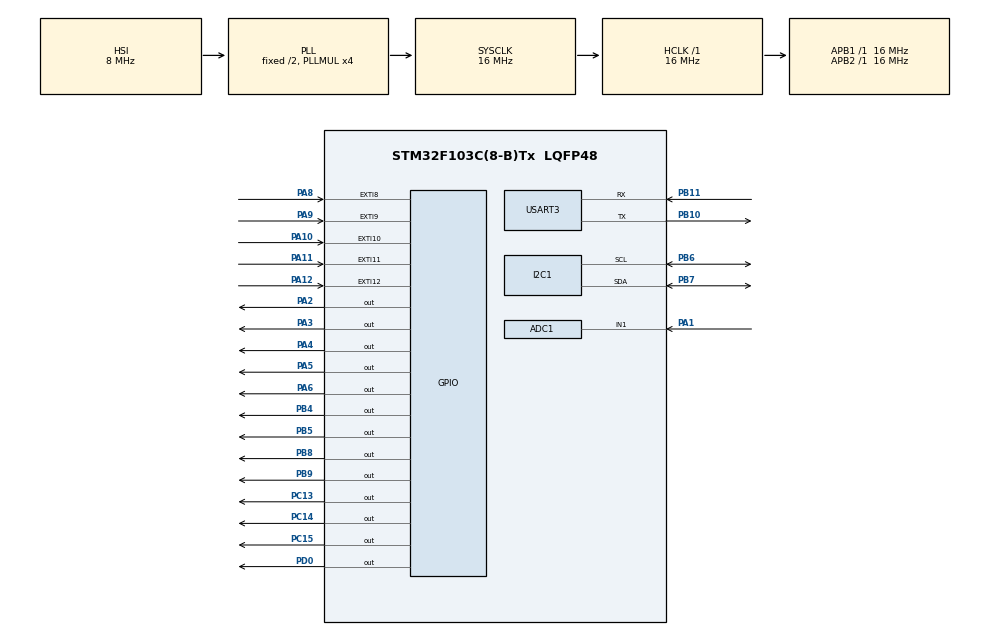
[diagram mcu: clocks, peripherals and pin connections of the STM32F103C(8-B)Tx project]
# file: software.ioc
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ADC1.Channel-0\#ChannelRegularConversion=ADC_CHANNEL_1
ADC1.NbrOfConversionFlag=1
ADC1.Rank-0\#ChannelRegularConversion=1
ADC1.SamplingTime-0\#ChannelRegularConversion=ADC_SAMPLETIME_1CYCLE_5
ADC1.master=1
Dma.Request0=USART3_TX
Dma.USART3_TX.0.Direction=DMA_MEMORY_TO_PERIPH
Dma.USART3_TX.0.Instance=DMA1_Channel2
Dma.USART3_TX.0.MemDataAlignment=DMA_MDATAALIGN_BYTE
Dma.USART3_TX.0.MemInc=DMA_MINC_ENABLE
Dma.USART3_TX.0.Mode=DMA_CIRCULAR
Dma.USART3_TX.0.PeriphDataAlignment=DMA_PDATAALIGN_BYTE
Dma.USART3_TX.0.PeriphInc=DMA_PINC_DISABLE
Dma.USART3_TX.0.Priority=DMA_PRIORITY_LOW
I2C1.I2C_Mode=I2C_Fast
Mcu.Family=STM32F1
Mcu.Name=STM32F103C(8-B)Tx
Mcu.Package=LQFP48
NVIC.DMA1_Channel2_IRQn=true\:0\:0\:false\:false\:true\:false\:true
NVIC.EXTI15_10_IRQn=true\:0\:0\:false\:false\:true\:true\:true
NVIC.EXTI9_5_IRQn=true\:0\:0\:false\:false\:true\:true\:true
NVIC.PriorityGroup=NVIC_PRIORITYGROUP_4
NVIC.TIM1_UP_IRQn=true\:0\:0\:false\:false\:true\:true\:true
NVIC.TIM2_IRQn=true\:0\:0\:false\:false\:true\:true\:true
NVIC.USART3_IRQn=true\:0\:0\:false\:false\:true\:true\:true
PA1.Signal=ADCx_IN1
PA10.GPIO_ModeDefaultEXTI=GPIO_MODE_IT_FALLING
PA10.GPIO_PuPd=GPIO_PULLUP
PA10.Signal=GPXTI10
PA11.GPIO_ModeDefaultEXTI=GPIO_MODE_IT_FALLING
PA11.GPIO_PuPd=GPIO_PULLUP
PA11.Signal=GPXTI11
PA12.GPIO_ModeDefaultEXTI=GPIO_MODE_IT_FALLING
PA12.GPIO_PuPd=GPIO_PULLUP
PA12.Signal=GPXTI12
PA13.Mode=Serial_Wire
PA13.Signal=SYS_JTMS-SWDIO
PA14.Mode=Serial_Wire
PA14.Signal=SYS_JTCK-SWCLK
PA2.Signal=GPIO_Output
PA3.Signal=GPIO_Output
PA4.Signal=GPIO_Output
PA5.Signal=GPIO_Output
PA6.Signal=GPIO_Output
PA8.GPIO_ModeDefaultEXTI=GPIO_MODE_IT_FALLING
PA8.GPIO_PuPd=GPIO_PULLUP
PA8.Signal=GPXTI8
PA9.GPIO_ModeDefaultEXTI=GPIO_MODE_IT_FALLING
PA9.GPIO_PuPd=GPIO_PULLUP
PA9.Signal=GPXTI9
PB10.Mode=Asynchronous
PB10.Signal=USART3_TX
PB11.Mode=Asynchronous
PB11.Signal=USART3_RX
PB4.Signal=GPIO_Output
PB5.Signal=GPIO_Output
PB6.Mode=I2C
PB6.Signal=I2C1_SCL
PB7.Mode=I2C
PB7.Signal=I2C1_SDA
PB8.Signal=GPIO_Output
PB9.Signal=GPIO_Output
PC13-TAMPER-RTC.Signal=GPIO_Output
PC14-OSC32_IN.Signal=GPIO_Output
PC15-OSC32_OUT.Signal=GPIO_Output
PD0-OSC_IN.Signal=GPIO_Output
ProjectManager.HeapSize=0x200
ProjectManager.StackSize=0x400
ProjectManager.TargetToolchain=MDK-ARM V5
RCC.AHBFreq_Value=16000000
RCC.APB1Freq_Value=16000000
RCC.APB1TimFreq_Value=16000000
RCC.APB2Freq_Value=16000000
RCC.APB2TimFreq_Value=16000000
RCC.HCLKFreq_Value=16000000
RCC.PLLMUL=RCC_PLL_MUL4
RCC.SYSCLKFreq_VALUE=16000000
RCC.SYSCLKSource=RCC_SYSCLKSOURCE_PLLCLK
RCC.USBFreq_Value=16000000
SH.ADCx_IN1.0=ADC1_IN1,IN1
TIM1.Prescaler=15999
TIM2.AutoReloadPreload=TIM_AUTORELOAD_PRELOAD_DISABLE
TIM2.Prescaler=15999
TIM2.TIM_MasterOutputTrigger=TIM_TRGO_RESET
USART3.VirtualMode=VM_ASYNC
VP_TIM1_VS_ClockSourceINT.Mode=Internal
VP_TIM2_VS_ClockSourceINT.Mode=Internal
board=custom

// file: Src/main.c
/* USER CODE BEGIN Header */
/**
  ******************************************************************************
  * @file           : main.c
  * @brief          : Main program body
  ******************************************************************************
  * @attention
  *
  * <h2><center>&copy; Copyright (c) 2019 STMicroelectronics.
  * All rights reserved.</center></h2>
  *
  * This software component is licensed by ST under BSD 3-Clause license,
  * the "License"; You may not use this file except in compliance with the
  * License. You may obtain a copy of the License at:
  *                        opensource.org/licenses/BSD-3-Clause
  *
  ******************************************************************************
  */
/* USER CODE END Header */

#include "main.h"
#include "adc.h"
#include "dma.h"
#include "i2c.h"
#include "tim.h"
#include "usart.h"
#include "gpio.h"

/* USER CODE BEGIN Includes */
#include "common.h"
#include "display.h"
#include "key.h"
/* USER CODE END Includes */

void SystemClock_Config(void);

int main(void)
{

  /* MCU Configuration--------------------------------------------------------*/

  /* Reset of all peripherals, Initializes the Flash interface and the Systick. */
  HAL_Init();

  /* Configure the system clock */
  SystemClock_Config();

  /* Initialize all configured peripherals */
  MX_GPIO_Init();
  MX_DMA_Init();
  MX_ADC1_Init();
  MX_TIM2_Init();
  MX_I2C1_Init();
  MX_USART3_UART_Init();
  MX_TIM1_Init();
  /* USER CODE BEGIN 2 */
  keyInit();
	ds3231Init();
  displayInit();
  /* USER CODE END 2 */

  /* Infinite loop */
  while (1)
  {

    /* USER CODE BEGIN 3 */
    longPressCheck();
    displayCheck();
  }
  /* USER CODE END 3 */
}

void SystemClock_Config(void)
{
  RCC_OscInitTypeDef RCC_OscInitStruct = {0};
  RCC_ClkInitTypeDef RCC_ClkInitStruct = {0};
  RCC_PeriphCLKInitTypeDef PeriphClkInit = {0};

  /** Initializes the CPU, AHB and APB busses clocks
  */
  RCC_OscInitStruct.OscillatorType = RCC_OSCILLATORTYPE_HSI;
  RCC_OscInitStruct.HSIState = RCC_HSI_ON;
  RCC_OscInitStruct.HSICalibrationValue = RCC_HSICALIBRATION_DEFAULT;
  RCC_OscInitStruct.PLL.PLLState = RCC_PLL_ON;
  RCC_OscInitStruct.PLL.PLLSource = RCC_PLLSOURCE_HSI_DIV2;
  RCC_OscInitStruct.PLL.PLLMUL = RCC_PLL_MUL4;
  if (HAL_RCC_OscConfig(&RCC_OscInitStruct) != HAL_OK)
  {
    Error_Handler();
  }
  /** Initializes the CPU, AHB and APB busses clocks
  */
  RCC_ClkInitStruct.ClockType = RCC_CLOCKTYPE_HCLK|RCC_CLOCKTYPE_SYSCLK
                              |RCC_CLOCKTYPE_PCLK1|RCC_CLOCKTYPE_PCLK2;
  RCC_ClkInitStruct.SYSCLKSource = RCC_SYSCLKSOURCE_PLLCLK;
  RCC_ClkInitStruct.AHBCLKDivider = RCC_SYSCLK_DIV1;
  RCC_ClkInitStruct.APB1CLKDivider = RCC_HCLK_DIV1;
  RCC_ClkInitStruct.APB2CLKDivider = RCC_HCLK_DIV1;

  if (HAL_RCC_ClockConfig(&RCC_ClkInitStruct, FLASH_LATENCY_0) != HAL_OK)
  {
    Error_Handler();
  }
  PeriphClkInit.PeriphClockSelection = RCC_PERIPHCLK_ADC;
  PeriphClkInit.AdcClockSelection = RCC_ADCPCLK2_DIV2;
  if (HAL_RCCEx_PeriphCLKConfig(&PeriphClkInit) != HAL_OK)
  {
    Error_Handler();
  }
}

void Error_Handler(void)
{
}

/************************ (C) COPYRIGHT STMicroelectronics *****END OF FILE****/
